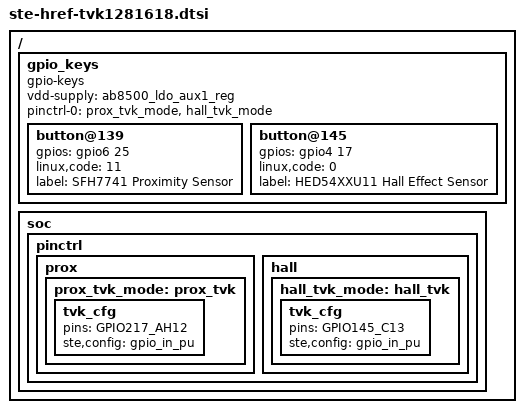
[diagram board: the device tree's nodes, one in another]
// SPDX-License-Identifier: GPL-2.0-or-later
/*
 * Copyright 2012 ST-Ericsson AB
 *
 * Device Tree for the TVK1281618 family of UIBs
 */

#include <dt-bindings/interrupt-controller/irq.h>

/ {
	gpio_keys {
		compatible = "gpio-keys";
		#address-cells = <1>;
		#size-cells = <0>;
		vdd-supply = <&ab8500_ldo_aux1_reg>;
		pinctrl-names = "default";
		pinctrl-0 = <&prox_tvk_mode>, <&hall_tvk_mode>;

		button@139 {
			/* Proximity sensor */
			gpios = <&gpio6 25 GPIO_ACTIVE_HIGH>;
			linux,code = <11>; /* SW_FRONT_PROXIMITY */
			label = "SFH7741 Proximity Sensor";
		};
		button@145 {
			/* Hall sensor */
			gpios = <&gpio4 17 GPIO_ACTIVE_HIGH>;
			linux,code = <0>; /* SW_LID */
			label = "HED54XXU11 Hall Effect Sensor";
		};
	};

	soc {
		pinctrl {
			prox {
				prox_tvk_mode: prox_tvk {
					tvk_cfg {
						pins = "GPIO217_AH12";
						ste,config = <&gpio_in_pu>;
					};
				};
			};
			hall {
				hall_tvk_mode: hall_tvk {
					tvk_cfg {
						pins = "GPIO145_C13";
						ste,config = <&gpio_in_pu>;
					};
				};
			};
		};
	};
};
